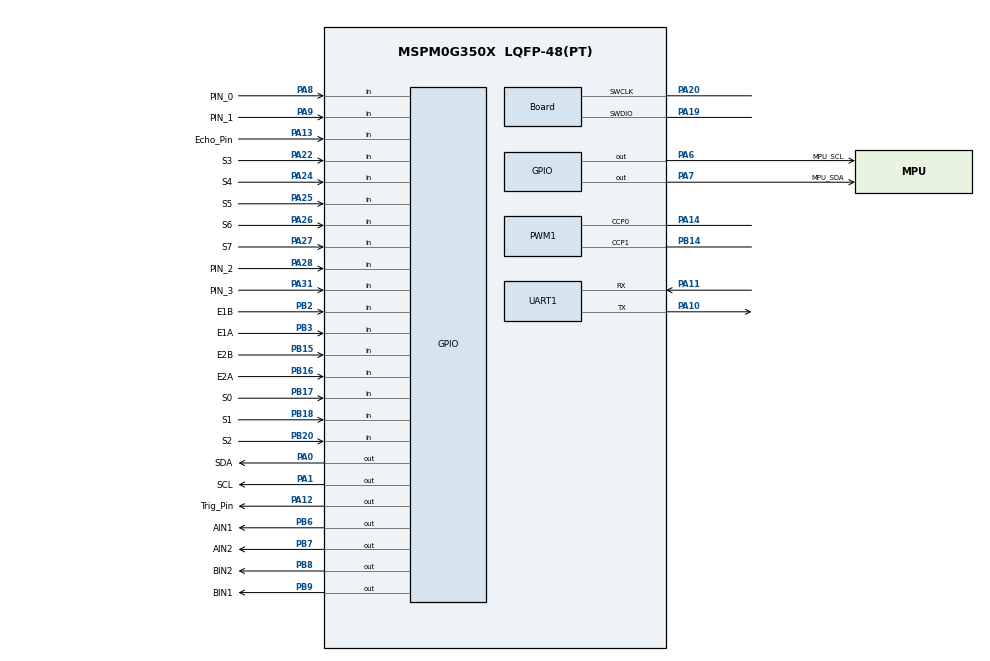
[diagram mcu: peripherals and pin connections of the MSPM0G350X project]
/**
 * @cliArgs --device "MSPM0G350X" --package "LQFP-48(PT)" --part "Default" --product "mspm0_sdk@2.01.00.03"
 * @versions {"tool":"1.20.0+3587"}
 */

/**
 * Import the modules used in this configuration.
 */
const GPIO          = scripting.addModule("/ti/driverlib/GPIO", {}, false);
const GPIO1         = GPIO.addInstance();
const GPIO2         = GPIO.addInstance();
const GPIO3         = GPIO.addInstance();
const GPIO4         = GPIO.addInstance();
const GPIO5         = GPIO.addInstance();
const GPIO6         = GPIO.addInstance();
const GPIO7         = GPIO.addInstance();
const GPIO8         = GPIO.addInstance();
const GPIO9         = GPIO.addInstance();
const PWM           = scripting.addModule("/ti/driverlib/PWM", {}, false);
const PWM1          = PWM.addInstance();
const SYSCTL        = scripting.addModule("/ti/driverlib/SYSCTL");
const TIMER         = scripting.addModule("/ti/driverlib/TIMER", {}, false);
const TIMER1        = TIMER.addInstance();
const TIMER2        = TIMER.addInstance();
const UART          = scripting.addModule("/ti/driverlib/UART", {}, false);
const UART1         = UART.addInstance();
const ProjectConfig = scripting.addModule("/ti/project_config/ProjectConfig");

/**
 * Write custom configuration values to the imported modules.
 */
const divider6       = system.clockTree["PLL_CLK2X_DIV"];
divider6.divideValue = 4;

const divider7       = system.clockTree["PLL_PDIV"];
divider7.divideValue = 2;

const divider9       = system.clockTree["UDIV"];
divider9.divideValue = 2;

const multiplier2         = system.clockTree["PLL_QDIV"];
multiplier2.multiplyValue = 10;

const mux8       = system.clockTree["HSCLKMUX"];
mux8.inputSelect = "HSCLKMUX_SYSPLL2X";

const pinFunction4       = system.clockTree["HFXT"];
pinFunction4.HFXTStartup = 10;

GPIO1.$name                         = "TRACK_SENSOR";
GPIO1.associatedPins.create(8);
GPIO1.associatedPins[0].direction   = "INPUT";
GPIO1.associatedPins[0].ioStructure = "SD";
GPIO1.associatedPins[0].$name       = "S0";
GPIO1.associatedPins[0].pin.$assign = "PB17";
GPIO1.associatedPins[1].$name       = "S1";
GPIO1.associatedPins[1].direction   = "INPUT";
GPIO1.associatedPins[1].ioStructure = "SD";
GPIO1.associatedPins[1].pin.$assign = "PB18";
GPIO1.associatedPins[2].$name       = "S2";
GPIO1.associatedPins[2].direction   = "INPUT";
GPIO1.associatedPins[2].ioStructure = "SD";
GPIO1.associatedPins[2].pin.$assign = "PB20";
GPIO1.associatedPins[3].$name       = "S3";
GPIO1.associatedPins[3].direction   = "INPUT";
GPIO1.associatedPins[3].ioStructure = "SD";
GPIO1.associatedPins[3].pin.$assign = "PA22";
GPIO1.associatedPins[4].$name       = "S4";
GPIO1.associatedPins[4].direction   = "INPUT";
GPIO1.associatedPins[4].ioStructure = "SD";
GPIO1.associatedPins[4].pin.$assign = "PA24";
GPIO1.associatedPins[5].$name       = "S5";
GPIO1.associatedPins[5].direction   = "INPUT";
GPIO1.associatedPins[5].ioStructure = "SD";
GPIO1.associatedPins[5].pin.$assign = "PA25";
GPIO1.associatedPins[6].$name       = "S6";
GPIO1.associatedPins[6].direction   = "INPUT";
GPIO1.associatedPins[6].ioStructure = "SD";
GPIO1.associatedPins[6].pin.$assign = "PA26";
GPIO1.associatedPins[7].$name       = "S7";
GPIO1.associatedPins[7].direction   = "INPUT";
GPIO1.associatedPins[7].ioStructure = "SD";
GPIO1.associatedPins[7].pin.$assign = "PA27";

const Board                       = scripting.addModule("/ti/driverlib/Board", {}, false);
Board.peripheral.$assign          = "DEBUGSS";
Board.peripheral.swclkPin.$assign = "PA20";
Board.peripheral.swdioPin.$assign = "PA19";

GPIO2.$name                         = "MOTOR";
GPIO2.associatedPins.create(4);
GPIO2.associatedPins[0].$name       = "AIN1";
GPIO2.associatedPins[0].pin.$assign = "PB6";
GPIO2.associatedPins[1].$name       = "AIN2";
GPIO2.associatedPins[1].pin.$assign = "PB7";
GPIO2.associatedPins[2].$name       = "BIN1";
GPIO2.associatedPins[2].pin.$assign = "PB9";
GPIO2.associatedPins[3].$name       = "BIN2";
GPIO2.associatedPins[3].pin.$assign = "PB8";

GPIO3.$name                              = "ENCODERA";
GPIO3.port                               = "PORTB";
GPIO3.associatedPins.create(2);
GPIO3.associatedPins[0].$name            = "E1A";
GPIO3.associatedPins[0].direction        = "INPUT";
GPIO3.associatedPins[0].interruptEn      = true;
GPIO3.associatedPins[0].internalResistor = "PULL_UP";
GPIO3.associatedPins[0].polarity         = "RISE_FALL";
GPIO3.associatedPins[0].pin.$assign      = "PB3";
GPIO3.associatedPins[1].$name            = "E1B";
GPIO3.associatedPins[1].direction        = "INPUT";
GPIO3.associatedPins[1].internalResistor = "PULL_UP";
GPIO3.associatedPins[1].interruptEn      = true;
GPIO3.associatedPins[1].polarity         = "RISE_FALL";
GPIO3.associatedPins[1].pin.$assign      = "PB2";

GPIO4.$name                               = "ENCODERB";
GPIO4.port                                = "PORTB";
GPIO4.associatedPins.create(2);
GPIO4.associatedPins[0].$name             = "E2A";
GPIO4.associatedPins[0].direction         = "INPUT";
GPIO4.associatedPins[0].internalResistor  = "PULL_UP";
GPIO4.associatedPins[0].interruptEn       = true;
GPIO4.associatedPins[0].interruptPriority = "0";
GPIO4.associatedPins[0].polarity          = "RISE_FALL";
GPIO4.associatedPins[0].pin.$assign       = "PB16";
GPIO4.associatedPins[1].$name             = "E2B";
GPIO4.associatedPins[1].direction         = "INPUT";
GPIO4.associatedPins[1].internalResistor  = "PULL_UP";
GPIO4.associatedPins[1].interruptPriority = "0";
GPIO4.associatedPins[1].interruptEn       = true;
GPIO4.associatedPins[1].polarity          = "RISE_FALL";
GPIO4.associatedPins[1].pin.$assign       = "PB15";

GPIO5.$name                         = "OLED_Pin";
GPIO5.port                          = "PORTA";
GPIO5.associatedPins.create(2);
GPIO5.associatedPins[0].$name       = "SDA";
GPIO5.associatedPins[0].pin.$assign = "PA0";
GPIO5.associatedPins[1].$name       = "SCL";
GPIO5.associatedPins[1].pin.$assign = "PA1";

GPIO6.$name                         = "Key_Pins";
GPIO6.port                          = "PORTA";
GPIO6.associatedPins.create(4);
GPIO6.associatedPins[0].$name       = "PIN_0";
GPIO6.associatedPins[0].direction   = "INPUT";
GPIO6.associatedPins[0].pin.$assign = "PA8";
GPIO6.associatedPins[1].$name       = "PIN_1";
GPIO6.associatedPins[1].direction   = "INPUT";
GPIO6.associatedPins[1].pin.$assign = "PA9";
GPIO6.associatedPins[2].$name       = "PIN_2";
GPIO6.associatedPins[2].direction   = "INPUT";
GPIO6.associatedPins[2].pin.$assign = "PA28";
GPIO6.associatedPins[3].$name       = "PIN_3";
GPIO6.associatedPins[3].direction   = "INPUT";
GPIO6.associatedPins[3].pin.$assign = "PA31";

GPIO7.$name                         = "Ultrasonic_Pins";
GPIO7.associatedPins.create(2);
GPIO7.associatedPins[0].$name       = "Trig_Pin";
GPIO7.associatedPins[0].pin.$assign = "PA12";
GPIO7.associatedPins[1].$name       = "Echo_Pin";
GPIO7.associatedPins[1].direction   = "INPUT";
GPIO7.associatedPins[1].pin.$assign = "PA13";

GPIO8.$name                   = "LEDB";
GPIO8.associatedPins[0].$name = "LED";

GPIO9.$name                              = "MPU6050";
GPIO9.port                               = "PORTA";
GPIO9.associatedPins.create(2);
GPIO9.associatedPins[0].$name            = "MPU_SDA";
GPIO9.associatedPins[0].internalResistor = "PULL_UP";
GPIO9.associatedPins[0].pin.$assign      = "PA7";
GPIO9.associatedPins[1].$name            = "MPU_SCL";
GPIO9.associatedPins[1].internalResistor = "PULL_UP";
GPIO9.associatedPins[1].pin.$assign      = "PA6";

PWM1.$name                      = "PWM_0";
PWM1.timerStartTimer            = true;
PWM1.pwmMode                    = "EDGE_ALIGN_UP";
PWM1.peripheral.$assign         = "TIMG12";
PWM1.peripheral.ccp0Pin.$assign = "PA14";
PWM1.peripheral.ccp1Pin.$assign = "PB14";
PWM1.PWM_CHANNEL_0.$name        = "ti_driverlib_pwm_PWMTimerCC0";
PWM1.PWM_CHANNEL_1.$name        = "ti_driverlib_pwm_PWMTimerCC1";
PWM1.ccp0PinConfig.$name        = "ti_driverlib_gpio_GPIOPinGeneric0";
PWM1.ccp0PinConfig.enableConfig = true;
PWM1.ccp1PinConfig.$name        = "ti_driverlib_gpio_GPIOPinGeneric1";
PWM1.ccp1PinConfig.enableConfig = true;

SYSCTL.forceDefaultClkConfig = true;
SYSCTL.clockTreeEn           = true;

TIMER1.$name              = "TIMER_0";
TIMER1.timerClkDiv        = 8;
TIMER1.timerClkPrescale   = 200;
TIMER1.timerPeriod        = "10 ms";
TIMER1.timerMode          = "PERIODIC";
TIMER1.timerStartTimer    = true;
TIMER1.interrupts         = ["ZERO"];
TIMER1.interruptPriority  = "0";
TIMER1.peripheral.$assign = "TIMA0";

TIMER2.$name              = "TIMER_US";
TIMER2.interrupts         = ["ZERO"];
TIMER2.timerMode          = "PERIODIC_UP";
TIMER2.timerPeriod        = "50us";
TIMER2.timerStartTimer    = true;
TIMER2.peripheral.$assign = "TIMG0";

UART1.$name                    = "UART_0";
UART1.targetBaudRate           = 115200;
UART1.peripheral.$assign       = "UART0";
UART1.peripheral.rxPin.$assign = "PA11";
UART1.peripheral.txPin.$assign = "PA10";
UART1.txPinConfig.$name        = "ti_driverlib_gpio_GPIOPinGeneric3";
UART1.rxPinConfig.$name        = "ti_driverlib_gpio_GPIOPinGeneric4";

ProjectConfig.deviceSpin = "MSPM0G3507";
scripting.suppress("Migrating requires going through the Switch Board or Device menu in the Device View section\\.", ProjectConfig, "deviceSpin");

/**
 * Pinmux solution for unlocked pins/peripherals. This ensures that minor changes to the automatic solver in a future
 * version of the tool will not impact the pinmux you originally saw.  These lines can be completely deleted in order to
 * re-solve from scratch.
 */
GPIO8.associatedPins[0].pin.$suggestSolution = "PA2";
